# SIMG301M103LIH register map
Vendor: Silicon Labs; Series: Si; File version: B
Registers are 32-bit, read-write, reset 0x0 unless marked. A register's access mark holds for its fields unless they carry their own. Offsets are from the block's base; [hi:lo] are bit positions; 'fields as' and 'values as' point back to an identical list.

## HFXO0_NS — HFXO0_NS Registers
Base 0x40104000
Same registers: HFXO0_S 0x50104000
0x00 IPVERSION ro reset 0x5
  [31:0] IPVERSION — IP Version ID
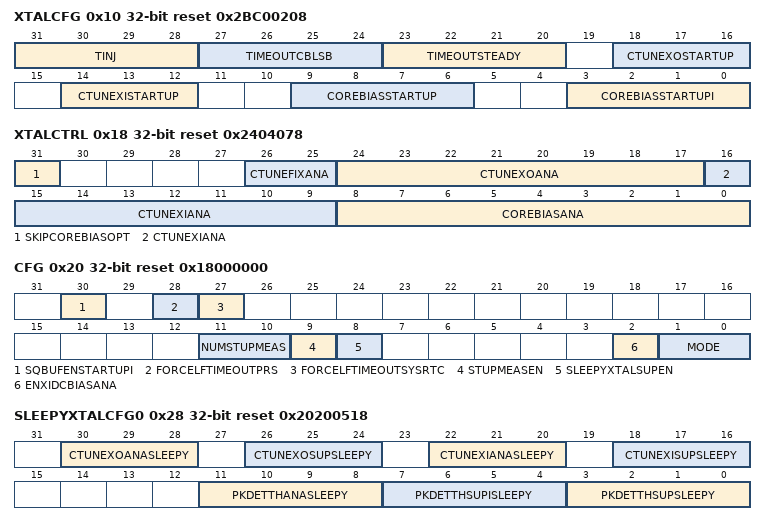
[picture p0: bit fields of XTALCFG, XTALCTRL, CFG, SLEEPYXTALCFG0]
0x10 XTALCFG reset 0x2BC00208
  [31:28] TINJ — Injection Time Configuration
    0=T10CYCLES (Clock injection for 10 xtal cycles (0.5us)); 1=T20CYCLES (Clock injection for 20 xtal cycles (1us)); 2=T30CYCLES (Clock injection for 30 xtal cycles (1.5us)); 3=T40CYCLES (Clock injection for 40 xtal cycles (2us)); 4=T50CYCLES (Clock injection for 50 xtal cycles (2.5us)); 5=T60CYCLES (Clock injection for 60 xtal cycles (3us)); 6=T70CYCLES (Clock injection for 70 xtal cycles (3.5us)); 7=T80CYCLES (Clock injection for 80 xtal cycles (4us)); 8=T90CYCLES (Clock injection for 90 xtal cycles (4.5us)); 9=T100CYCLES (Clock injection for 100 xtal cycles (5us)); 10=T110CYCLES (Clock injection for 110 xtal cycles (5.5us)); 11=T120CYCLES (Clock injection for 120 xtal cycles (6us)); 12=T130CYCLES (Clock injection for 130 xtal cycles (6.5us)); 13=T140CYCLES (Clock injection for 140 xtal cycles (7us)); 14=T180CYCLES (Clock injection for 180 xtal cycles (9us)); 15=T210CYCLES (Clock injection for 210 xtal cycles (10.5us))
  [27:24] TIMEOUTCBLSB — Core Bias LSB Change Timeout
    0=T8US (The core bias LSB change timeout is set to 8 us minimum. The maximum can be +40%.); 1=T20US (The core bias LSB change timeout is set to 20 us minimum. The maximum can be +40%.); 2=T41US (The core bias LSB change timeout is set to 41 us minimum. The maximum can be +40%.); 3=T62US (The core bias LSB change timeout is set to 62 us minimum. The maximum can be +40%.); 4=T83US (The core bias LSB change timeout is set to 83 us minimum. The maximum can be +40%.); 5=T104US (The core bias LSB change timeout is set to 104 us minimum. The maximum can be +40%.); 6=T125US (The core bias LSB change timeout is set to 125 us minimum. The maximum can be +40%.); 7=T166US (The core bias LSB change timeout is set to 166 us minimum. The maximum can be +40%.); 8=T208US (The core bias LSB change timeout is set to 208 us minimum. The maximum can be +40%.); 9=T250US (The core bias LSB change timeout is set to 250 us minimum. The maximum can be +40%.); 10=T333US (The core bias LSB change timeout is set to 333 us minimum. The maximum can be +40%.); 11=T416US (The core bias LSB change timeout is set to 416 us minimum. The maximum can be +40%.); 12=T833US (The core bias LSB change timeout is set to 833 us minimum. The maximum can be +40%.); 13=T1250US (The core bias LSB change timeout is set to 1250 us minimum. The maximum can be +40%.); 14=T2083US (The core bias LSB change timeout is set to 2083 us minimum. The maximum can be +40%.); 15=T3750US (The core bias LSB change timeout is set to 3750 us minimum. The maximum can be +40%.)
  [23:20] TIMEOUTSTEADY — Steady State Timeout
    0=T4US (The steady state timeout is set to 4 us minimum. The maximum can be +40%.); 1=T16US (The steady state timeout is set to 16 us minimum. The maximum can be +40%.); 2=T41US (The steady state timeout is set to 41 us minimum. The maximum can be +40%.); 3=T83US (The steady state timeout is set to 83 us minimum. The maximum can be +40%.); 4=T125US (The steady state timeout is set to 125 us minimum. The maximum can be +40%.); 5=T166US (The steady state timeout is set to 166 us minimum. The maximum can be +40%.); 6=T208US (The steady state timeout is set to 208 us minimum. The maximum can be +40%.); 7=T250US (The steady state timeout is set to 250 us minimum. The maximum can be +40%.); 8=T333US (The steady state timeout is set to 333 us minimum. The maximum can be +40%.); 9=T416US (The steady state timeout is set to 416 us minimum. The maximum can be +40%.); 10=T500US (The steady state timeout is set to 500 us minimum. The maximum can be +40%.); 11=T666US (The steady state timeout is set to 666 us minimum. The maximum can be +40%.); 12=T833US (The steady state timeout is set to 833 us minimum. The maximum can be +40%.); 13=T1666US (The steady state timeout is set to 1666 us minimum. The maximum can be +40%.); 14=T2500US (The steady state timeout is set to 2500 us minimum. The maximum can be +40%.); 15=T4166US (The steady state timeout is set to 4166 us minimum. The maximum can be +40%.)
  [18:16] CTUNEXOSTARTUP — Startup Tuning Capacitance on XO
  [14:12] CTUNEXISTARTUP — Startup Tuning Capacitance on XI
  [9:6] COREBIASSTARTUP — Startup Core Bias Current
  [3:0] COREBIASSTARTUPI — Intermediate Startup Core Bias Current
0x18 XTALCTRL reset 0x2404078
  [31] SKIPCOREBIASOPT — Skip Core Bias Optimization
  [26:25] CTUNEFIXANA — Fixed Tuning Capacitance
    0=NONE (Remove fixed capacitance on XO node); 1=SEL0 (Adds fixed capacitance of 1.31pF on XO node); 2=SEL1 (Adds fixed capacitance of 2.62pF on XO node); 3=SEL2 (Adds fixed capacitance of 3.93pF on XO node)
  [24:17] CTUNEXOANA — Tuning Capacitance on XO
  [16:9] CTUNEXIANA — Tuning Capacitance on XI
  [8:0] COREBIASANA — Core Bias Current
0x20 CFG reset 0x18000000
  [30] SQBUFENSTARTUPI — Early enable for Squaring Buffer
  [28] FORCELFTIMEOUTPRS — Force PRS Low Frequency Timeout
  [27] FORCELFTIMEOUTSYSRTC — Force SYSRTC Low Frequency Timeout
  [11:10] NUMSTUPMEAS — Number of startup time measurements
    0=MEASURE1 (Measure and average over 1 startup time samples); 1=MEASURE8 (Measure and average over 8 startup time samples); 2=MEASURE16 (Measure and average over 16 startup time samples)
  [9] STUPMEASEN — Enable startup time measurement logic
  [8] SLEEPYXTALSUPEN — Enable sleepy crystal startup logic
  [2] ENXIDCBIASANA — Enable XI Internal DC Bias
  [1:0] MODE — Crystal Oscillator Mode
    0=XTAL (crystal oscillator); 1=EXTCLK (external sinusoidal clock can be supplied on XI pin.); 2=EXTCLKPKDET (external sinusoidal clock can be supplied on XI pin (peak detector used).)
0x28 SLEEPYXTALCFG0 reset 0x20200518
  [30:28] CTUNEXOANASLEEPY — XI pin tuning cap after startup
  [26:24] CTUNEXOSUPSLEEPY — XI pin tuning cap during startup
  [22:20] CTUNEXIANASLEEPY — XI pin tuning cap after startup
  [18:16] CTUNEXISUPSLEEPY — XI pin tuning cap during startup
  [11:8] PKDETTHANASLEEPY — Steady State Peak Detector Threshold
  [7:4] PKDETTHSUPISLEEPY — Startup Intermediate Pkdet Threshold
  [3:0] PKDETTHSUPSLEEPY — Startup Peak Detector Threshold
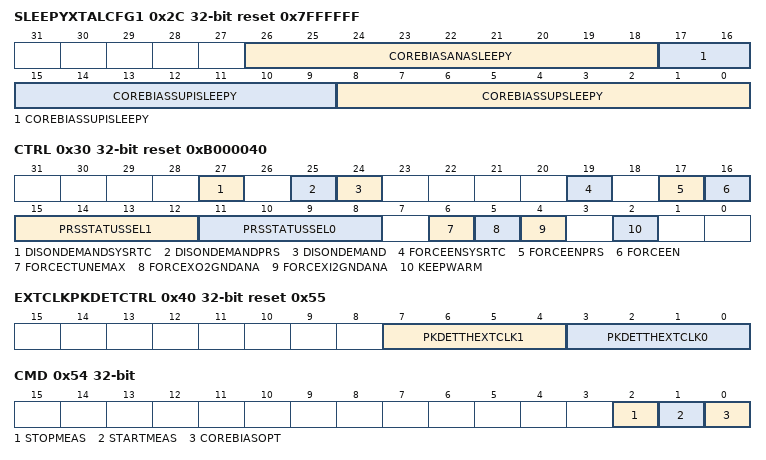
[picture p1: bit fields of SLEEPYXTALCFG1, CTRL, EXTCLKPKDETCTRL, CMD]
0x2C SLEEPYXTALCFG1 reset 0x7FFFFFF
  [26:18] COREBIASANASLEEPY — Steady Phase Core Bias Setting
  [17:9] COREBIASSUPISLEEPY — Startup Intermediate Phase Core Bias
  [8:0] COREBIASSUPSLEEPY — Startup Phase Core Bias
0x30 CTRL reset 0xB000040
  [27] DISONDEMANDSYSRTC — Disable On-demand For SYSRTC
  [25] DISONDEMANDPRS — Disable On-demand For PRS
  [24] DISONDEMAND — Disable On-demand For Digital Clock
  [19] FORCEENSYSRTC — Force SYSRTC Oscillator Request
  [17] FORCEENPRS — Force PRS Oscillator Request
  [16] FORCEEN — Force Digital Clock Request
  [15:12] PRSSTATUSSEL1 — PRS Status 1 Output Select
    0=DISABLED (PRS mux outputs 0); 1=ENS (PRS mux outputs enabled status); 2=COREBIASOPTRDY (PRS mux outputs core bias optimization ready status); 3=RDY (PRS mux outputs ready status); 4=PRSRDY (PRS mux outputs PRS ready status); 5=SYSRTCRDY (PRS mux outputs SYSRTC ready status); 9=HWREQ (PRS mux outputs oscillator requested by digital clock status); 10=PRSHWREQ (PRS mux outputs oscillator requested by PRS request status); 11=SYSRTCHWREQ (PRS mux outputs oscillator requested by SYSRTC request status)
  [11:8] PRSSTATUSSEL0 — PRS Status 0 Output Select
    values as PRSSTATUSSEL1
  [6] FORCECTUNEMAX — Force Tuning Cap to Max Value
  [5] FORCEXO2GNDANA — Force XO Pin to Ground
    0=DISABLE (Disabled (not pulled)); 1=ENABLE (Enabled (pulled))
  [4] FORCEXI2GNDANA — Force XI Pin to Ground
    values as FORCEXO2GNDANA
  [2] KEEPWARM
0x40 EXTCLKPKDETCTRL reset 0x55 — Peak Detector Control Register in EXTCLKPKDET mode
  [7:4] PKDETTHEXTCLK1 — PKDET Threshold1 EXTCLKPKDET mode
  [3:0] PKDETTHEXTCLK0 — PKDET Threshold0 EXTCLKPKDET mode
0x54 CMD wo
  [2] STOPMEAS — Stop measuring crystal startup time
  [1] STARTMEAS — Start measuring crystal startup time
  [0] COREBIASOPT — Core Bias Optimizaton
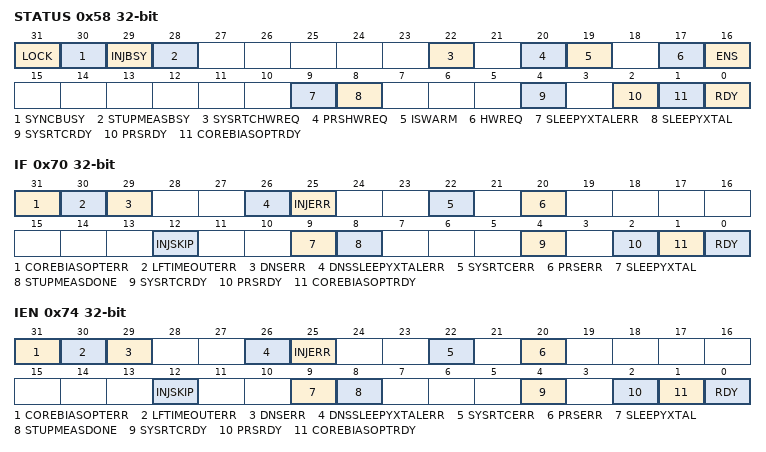
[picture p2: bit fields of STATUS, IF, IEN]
0x58 STATUS ro
  [31] LOCK — Configuration Lock Status
    0=UNLOCKED (Configuration lock is unlocked); 1=LOCKED (Configuration lock is locked)
  [30] SYNCBUSY
  [29] INJBSY — Clock Injection Busy
  [28] STUPMEASBSY — Startup Measurement Busy
  [22] SYSRTCHWREQ — Oscillator Requested by SYSRTC Request
  [20] PRSHWREQ — Oscillator Requested by PRS Request
  [19] ISWARM — Oscillator Is Kept Warm
  [17] HWREQ — Oscillator Requested by Digital Clock
  [16] ENS — Enabled Status
  [9] SLEEPYXTALERR — XTAL Startup Failed with Sleepy Settings
  [8] SLEEPYXTAL — Sleepy XTAL settings applied
  [4] SYSRTCRDY — SYSRTC Ready Status
  [2] PRSRDY — PRS Ready Status
  [1] COREBIASOPTRDY — Core Bias Optimization Ready
  [0] RDY — Ready Status
0x5C AVGSTARTUPTIME ro
  [8:0] AVGSTUP — Average Startup Time
0x70 IF
  [31] COREBIASOPTERR — Core Bias Optimization Error Interrupt
  [30] LFTIMEOUTERR — Low Frequency Timeout Error Interrupt
  [29] DNSERR — Did Not Start Error Interrupt
  [26] DNSSLEEPYXTALERR — Did Not Start Sleepy Xtal Error IRQ
  [25] INJERR — Injection Error Interrupt
  [22] SYSRTCERR — SYSRTC Request Error Interrupt
  [20] PRSERR — PRS Requset Error Interrupt
  [12] INJSKIP — Injection Skipped
  [9] SLEEPYXTAL — Sleepy crystal settings applied
  [8] STUPMEASDONE — Startup Time Measurement Complete
  [4] SYSRTCRDY — SYSRTC Ready Interrupt
  [2] PRSRDY — PRS Ready Interrupt
  [1] COREBIASOPTRDY — Core Bias Optimization Ready Interrupt
  [0] RDY — Digital Clock Ready Interrupt
0x74 IEN
  fields as IF
0x80 LOCK wo reset 0x580E
  [15:0] LOCKKEY — Configuration Lock Key
    0x580E=UNLOCK (Write this value to unlock)
